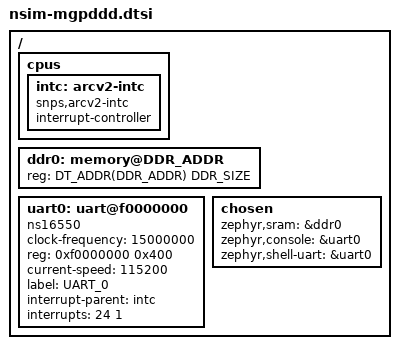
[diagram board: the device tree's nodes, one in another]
/*
 * Copyright (c) 2018, 2019, Synopsys, Inc. All rights reserved.
 *
 * SPDX-License-Identifier: Apache-2.0
 */

/dts-v1/;

#include "skeleton.dtsi"
#include <mem.h>

#ifndef DDR_ADDR
#define DDR_ADDR 10000000
#endif

#ifndef DDR_SIZE
#define DDR_SIZE DT_SIZE_M(1)
#endif

/ {
	cpus {
		#address-cells = <1>;
		#size-cells = <0>;

		intc: arcv2-intc {
			compatible = "snps,arcv2-intc";
			interrupt-controller;
			#interrupt-cells = <2>;
		};
	};

	ddr0: memory@DDR_ADDR {
		device_type = "memory";
		reg = <DT_ADDR(DDR_ADDR) DDR_SIZE>;
	};

	uart0: uart@f0000000 {
		compatible = "ns16550";
		clock-frequency = <15000000>;
		reg = <0xf0000000 0x400>;
		current-speed = <115200>;
		label = "UART_0";
		interrupt-parent = <&intc>;
		interrupts = <24 1>;
	};

	chosen {
		zephyr,sram = &ddr0;
		zephyr,console = &uart0;
		zephyr,shell-uart = &uart0;
	};
};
